# NUC400_v1 register map
File version: 1.0
Registers are 32-bit, read-write, reset 0x0 unless marked. A register's access mark holds for its fields unless they carry their own. Offsets are from the block's base; [hi:lo] are bit positions; 'fields as' and 'values as' point back to an identical list.

## EPWM0 — EPWM Register Map
Base 0x4005C000
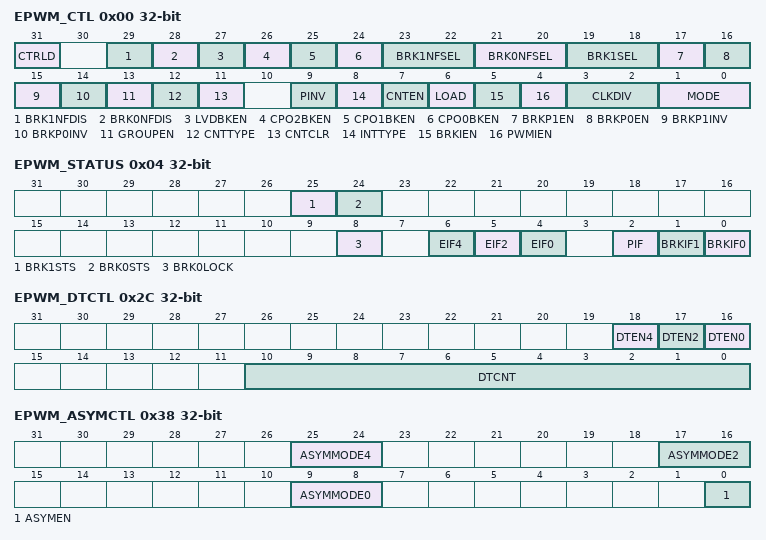
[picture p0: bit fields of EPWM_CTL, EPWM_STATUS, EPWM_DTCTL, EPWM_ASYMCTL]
0x00 EPWM_CTL — PWM Control Register
  [31] CTRLD — Center Reload Mode Enable Bit. This bit only work when EPWM operation at center aligned mode.
    0=EPWM reload compare register at the period point of PWM counter; 1=EPWM reload compare register at the center point of PWM counter
  [29] BRK1NFDIS — PWM Brake 1 Noise Filter Disable Bit
    0=Noise filter of PWM Brake 1 Enabled; 1=Noise filter of PWM Brake 1 Disabled
  [28] BRK0NFDIS — PWM Brake 0 Noise Filter Disable Bit
    0=Noise filter of PWM Brake 0 Enabled; 1=Noise filter of PWM Brake 0 Disabled
  [27] LVDBKEN — Low-Level Detection Trigger PWM Brake Function 1 Enable Bit
    0=Brake Function 1 triggered by Low-level detection Disabled; 1=Brake Function 1 triggered by Low-level detection Enabled
  [26] CPO2BKEN — CPO2 Digital Output As Brake 0 Source Enable Bit
    0=CPO2 as one brake source in Brake 0 Disabled; 1=CPO2 as one brake source in Brake 0 Enabled
  [25] CPO1BKEN — CPO1 Digital Output As Brake 0 Source Enable Bit
    0=CPO1 as one brake source in Brake 0 Disabled; 1=CPO1 as one brake source in Brake 0 Enabled
  [24] CPO0BKEN — CPO0 Digital Output As Brake0 Source Enable Bit
    0=CPO0 as one brake source in Brake 0 Disabled; 1=CPO0 as one brake source in Brake 0 Enabled
  [23:22] BRK1NFSEL — Brake 1 (BKPx1 Pin) Edge Detector Filter Clock Selection
    0=Filter clock = HCLK; 1=Filter clock = HCLK/2; 2=Filter clock = HCLK/4; 3=Filter clock = HCLK/16
  [21:20] BRK0NFSEL — Brake 0 (BKPx0 Pin) Edge Detector Filter Clock Selection
    values as BRK1NFSEL
  [19:18] BRK1SEL — Brake Function 1 Source Selection
    0=From external pin BKPx1 (x=0~1 for unit0~1); 1=From analog comparator 0 output (CPO0); 2=From analog comparator 1 output (CPO1); 3=From analog comparator 2 output (CPO2)
  [17] BRKP1EN — BKPx1 Pin Trigger Brake Function Enable Bit
    0=PWMx Brake Function 1 Disabled; 1=PWMx Brake Function 1 Enabled
  [16] BRKP0EN — BKPx0 Pin Trigger Brake Function0 Enable Bit
    0=PWMx Brake Function 0 Disabled; 1=PWMx Brake Function 0 Enabled
  [15] BRKP1INV — Inverse BKP1 State
    0=The state of pin BKPx1 is passed to the negative edge detector; 1=The inversed state of pin BKPx1 is passed to the negative edge detector
  [14] BRKP0INV — Inverse BKP0 State
    0=The state of pin BKPx0 is passed to the negative edge detector; 1=The inversed state of pin BKPx0 is passed to the negative edge detector
  [13] GROUPEN — Group Bit
    0=The signals timing of EPWM_CMPDAT0, EPWM_CMPDAT2 and EPWM_CMPDAT4 are independent; 1=Unify the signals timing of EPWM_CMPDAT0, EPWM_CMPDAT2 and EPWM_CMPDAT4 in the same phase which is controlled by EPWM_CMPDAT0
  [12] CNTTYPE — PWM Aligned Type Selection
    0=Edge-aligned type; 1=Centre-aligned type
  [11] CNTCLR — Clear PWM Counter Control. Note: It is automatically cleared by hardware.
    1=Clear 16-bit PWM counter to 000H
  [9] PINV — Inverse PWM Comparator Output. When PINV is set to high the PWM comparator output signals will be inversed, therefore the PWM Duty (in percentage) is changed to (1-Duty) before PINV is set to high.
    0=Not inverse PWM comparator output; 1=Inverse PWM comparator output
  [8] INTTYPE — PWM Interrupt Type Selection. Note: This bit is effective when PWM in central align mode only.
    0=PIF will be set if PWM counter underflow; 1=PIF will be set if PWM counter matches EPWM_PERIOD register
  [7] CNTEN — Start CNTEN Control
    0=The PWM stops running; 1=The PWM counter starts running
  [6] LOAD — Re-Load PWM Period Registers (EPWM_PERIOD) And PWM Compare Registers (EPWM_CMPDAT0~4) Control. Note: This bit is software write, hardware clear and always read zero.
    0=No action if written with 0. The value of PWM period register (EPWM_PERIOD) and PWM compare registers (EPWM_CMPDAT0~EPWM_CMPDAT4) are not loaded to PWM counter and Comparator registers; 1=Hardware will update the value of PWM period register (EPWM_PERIOD) and PWM compare registers (EPWM_CMPDAT0~EPWM_CMPDAT4) to PWM Counter and Comparator register at the time of PWM Counter matches PERIOD in edge and central aligned modes or at the time of PWM Counter down counts with underflow in central aligned mode
  [5] BRKIEN — Brake0 And Brak1 Interrupt Enable Bit
    0=Disabling flags BRKIF0 and BRKIF1 to trigger PWM interrupt; 1=Enabling flags BRKIF0 and BRKIF1 can trigger PWM interrupt
  [4] PWMIEN — PWM Interrupt Enable Bit
    0=Disabling flag PIF to trigger PWM interrupt; 1=Enabling flag PIF can trigger PWM interrupt
  [3:2] CLKDIV — PWM Clock Pre-Divider Selection
    0=PWM clock = EPWM_CLK; 1=PWM clock = EPWM_CLK/2; 2=PWM clock = EPWM_CLK/4; 3=PWM clock = EPWM_CLK/16
  [1:0] MODE — PWM Mode Selection
    0=Independent mode; 1=Pair/Complementary mode; 2=Synchronized mode
0x04 EPWM_STATUS — PWM Status Register
  [25] BRK1STS ro — Brake 1 Status (Read Only)
    0=PWM had been out of Brake 1 state; 1=PWM is in Brake 1 state
  [24] BRK0STS ro — Brake 0 Status (Read Only)
    0=PWM had been out of Brake 0 state; 1=PWM is in Brake 0 state
  [8] BRK0LOCK — PWM Brake0 Locked. Note: This bit must be cleared by writing 1 to it.
    0=Brake 0 state is released; 1=When PWM Brake detects a falling signal at BKP0, this flag will be set to high to indicate the Brake0 state is locked
  [6] EIF4 — PWMx_CH4 Edge Flag. Note: This bit must be cleared by writing 1 to it.
    0=The PWMx_CH4 doesn't toggle; 1=Hardware will set this flag to high at the time of PWMx_CH4 rising or falling. If EDGEIEN4(EPWM_EINTCTL[10]) = 0, this bit is set when PWMx_CH4 falling is detected. If EDGEIEN4(EPWM_EINTCTL[10]) = 1, this bit is set when PWMx_CH4 rising is detected.
  [5] EIF2 — PWMx_CH2 Edge Flag. Note: This bit must be cleared by writing 1 to it.
    0=The PWMx_CH2 doesn't toggle; 1=Hardware will set this flag to high at the time of PWMx_CH2 rising or falling. If EDGEIEN2(EPWM_EINTCTL[9]) = 0, this bit is set when PWMx_CH2 falling is detected. If EDGEIEN2(EPWM_EINTCTL[9])= 1, this bit is set when PWMx_CH2 rising is detected.
  [4] EIF0 — PWMx_CH0 Edge Flag. Note: This bit must be cleared by writing 1 to it.
    0=The PWMx_CH0 doesn't toggle; 1=Hardware will set this flag to high at the time of PWMx_CH0 rising or falling. If EDGEIEN0(EPWM_EINTCTL[8]) = 0, this bit is set when PWMx_CH0 falling is detected. If EDGEIEN0(EPWM_EINTCTL[8]) = 1, this bit is set when PWMx_CH0 rising is detected.
  [2] PIF — PWM Period Flag. Note: This bit must be cleared by writing 1 to it.
    0=PWM Counter has not up counted to the value of PERIOD or down counted with underflow; 1=Hardware will set this flag to high at the time of PWM Counter matches PERIOD in edge and Centre aligned modes or at the time of PWM Counter down counts with underflow in Centre aligned mode
  [1] BRKIF1 — PWM Brake1 Flag. Note: This bit must be cleared by writing 1 to it.
    0=PWM Brake 1 is able to poll falling signal at BKP1 and has not recognized any one; 1=When PWM Brake 1 detects a falling signal at pin BKP1, this flag will be set to high
  [0] BRKIF0 — PWM Brake0 Flag. Note: This bit must be cleared by writing 1 to it.
    0=PWM Brake 0 is able to poll falling signal at BKP0 and has not recognized any one; 1=When PWM Brake 0 detects a falling signal at BKP0, this flag will be set to high
0x08 EPWM_PERIOD — PWM Period Register
  [15:0] PERIOD — PWM Period Register. Edge aligned:
0x0C EPWM_CMPDAT0 — EPWM_CMPDAT0 Duty Register
  [15:0] CMP — PWM Duty Register. Edge aligned:
0x10 EPWM_CMPDAT2 — EPWM_CMPDAT2 Duty Register
  [15:0] CMP — PWM Duty Register. Edge aligned:
0x14 EPWM_CMPDAT4 — EPWM_CMPDAT4 Duty Register
  [15:0] CMP — PWM Duty Register. Edge aligned:
0x18 EPWM_MSKEN — PWM Mask Mode Enable Control Register
  [5:0] MSKEN — PWM Mask Enable Bits. The PWM generator signal will be masked when this bit is enabled. The corresponding EPWM_CHn channel will be output with EPWM_MSK[n] data.
    0=PWM generator signal is output to next stage; 1=PWM generator signal is masked and EPWM_MSK[n] is output to next stage
0x1C EPWM_MSK — PWM Mask Mode Data Register
  [5:0] MSKDAT — PWM Mask Data Bit
    0=Output logic low to EPWM_CHn; 1=Output logic high to EPWM_CHn
0x20 EPWM_ASYMCMP0 — Asymmetric EPWM_CMPDAT0 Duty Register
  [15:0] CMP — Asymmetric PWM Duty Register. When the asymmetric PWM function is enabled, this 16-bit field determines the second time compared value after PWM counter has matched with EPWM_CMPDATx in the first half PWM cycle.
0x24 EPWM_ASYMCMP2 — Asymmetric EPWM_CMPDAT2 Duty Register
  fields as EPWM_ASYMCMP0
0x28 EPWM_ASYMCMP4 — Asymmetric EPWM_CMPDAT4 Duty Register
  fields as EPWM_ASYMCMP0
0x2C EPWM_DTCTL — PWM Dead-time Control Register
  [18] DTEN4 — Dead-Time Insertion Enable Control for PWMx Pair (PWM_CH4, PWM_CH5). Dead-time insertion is only active when this pair of complementary PWM is enabled. If dead-time insertion is inactive, the outputs of pin pair are complementary without any delay.
    0=Dead-time insertion Disabled on the pin pair (PWM_CH4, PWM_CH5); 1=Dead-time insertion Enabled on the pin pair (PWM_CH4, PWM_CH5)
  [17] DTEN2 — Dead-Time Insertion Enable Control for PWMx Pair (PWM_CH2, PWM_CH3). Dead-time insertion is only active when this pair of complementary PWM is enabled. If dead-time insertion is inactive, the outputs of pin pair are complementary without any delay.
    0=Dead-time insertion Disabled on the pin pair (PWM_CH2, PWM_CH3); 1=Dead-time insertion Enabled on the pin pair (PWM_CH2, PWM_CH3)
  [16] DTEN0 — Dead-Time Insertion Enable Control for PWMx Pair (PWM_CH0, PWM_CH1). Dead-time insertion is only active when this pair of complementary PWM is enabled. If dead-time insertion is inactive, the outputs of pin pair are complementary without any delay.
    0=Dead-time insertion Disabled on the pin pair (PWM_CH0, PWM_CH1); 1=Dead-time insertion Enabled on the pin pair (PWM_CH0, PWM_CH1)
  [10:0] DTCNT — Dead-Time Counter. The dead-time can be calculated from the following formula:
0x30 EPWM_BRKOUT — PWM Brake Output
  [5:0] BRKOUT — PWM Brake Output. When PWM Brake is asserted, the PWM_CH0~5 output state before polarity control will follow bit0~5 setting, respectively.
    0=The PWM_CHn output before polarity control is low when Brake is asserted; 1=The PWM_CHn output before polarity control is high when Brake is asserted
0x34 EPWM_NPCTL — PWM Negative Polarity Control
  [5:0] NEGPOLAR — PWM Negative Polarity Control. The register bit controls polarity/active state of real PWM output.
    0=PWM_CHn output is active high; 1=PWM_CHn output is active low
0x38 EPWM_ASYMCTL — Asymmetric PWM Control Register
  [25:24] ASYMMODE4 — Asymmetric PWMx_CH4 Reload Mode Setting
    0=1. PWM compare register 4 is reload CMP (EPWM_CMPDAT4[15:0]) at PWM cycle start; 1=1. PWM compare register 4 is reload CMP (EPWM_CMPDAT4[15:0]) at PWM cycle start; 2=1. PWM compare register 4 is reload CMP (EPWM_CMPDAT4[15:0]) at PWM cycle start
  [17:16] ASYMMODE2 — Asymmetric PWMx_CH2 Reload Mode Setting
    0=1. PWM compare register 2 is reload CMP (EPWM_CMPDAT2[15:0]) at PWM cycle start; 1=1. PWM compare register 2 is reload CMP (EPWM_CMPDAT2[15:0]) at PWM cycle start; 2=1. PWM compare register 2 is reload PWM_Duty (PWMx2[15:0]) at PWM cycle start
  [9:8] ASYMMODE0 — Asymmetric PWMx_CH0 Reload Mode Setting
    0=1. PWM compare register 0 is reload CMP (EPWM_CMPDAT0[15:0]) at PWM cycle start; 1=1. PWM compare register 0 is reload CMP (EPWM_CMPDAT0[15:0]) at PWM cycle start; 2=1. PWM compare register 0 is reload CMP (EPWM_CMPDAT0[15:0]) at PWM cycle start
  [0] ASYMEN — Asymmetric PWM Enable Bit. Note: This control bit is only valid when PWM module is set in Centre-aligned mode.
    0=Asymmetric PWM function Disabled; 1=Asymmetric PWM function Enabled
0x3C EPWM_PERIODCNT — PIF Compared Counter
  [3:0] PERIODCNT — PIF Compared Counter. The register sets the count number which defines how many times of PWM period occurs to set bit PIF to request the PWM period interrupt. PIF will be set in every (1 + PERIODCNT[3:0]) times of PWM period or center point defined by INTTYPE when EPWM_CTL [8] occurred.
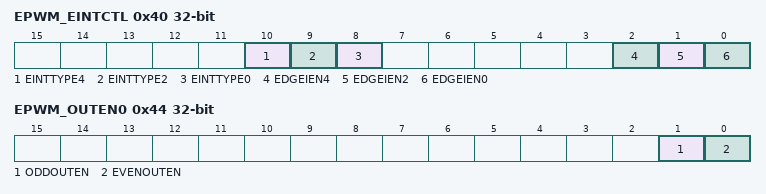
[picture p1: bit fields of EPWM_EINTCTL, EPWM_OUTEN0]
0x40 EPWM_EINTCTL — PWM Edge Interrupt Control Register
  [10] EINTTYPE4 — PWMx4 Edge Interrupt Type
    0=EIF4 will be set if falling edge is detected at PWMx4; 1=EIF4 will be set if rising edge is detected at PWMx4
  [9] EINTTYPE2 — PWMx2 Edge Interrupt Type
    0=EIF2 will be set if falling edge is detected at PWMx2; 1=EIF2 will be set if rising edge is detected at PWMx2
  [8] EINTTYPE0 — PWMx0 Edge Interrupt Type
    0=EIF0 will be set if falling edge is detected at PWMx0; 1=EIF0 will be set if rising edge is detected at PWMx0
  [2] EDGEIEN4 — PWMx4 Edge Interrupt Enable Bit
    0=Disable flag EIF4 to trigger PWM interrupt; 1=Enabling flag EIF4 can trigger PWM interrupt
  [1] EDGEIEN2 — PWMx2 Edge Interrupt Enable Bit
    0=Disabling flag EIF2 can trigger PWM interrupt; 1=Enabling flag EIF2 can trigger PWM interrupt
  [0] EDGEIEN0 — PWMx0 Edge Interrupt Enable Bit
    0=Disabling flag EIF0 to trigger PWM interrupt; 1=Enabling flag EIF0 can trigger PWM interrupt
0x44 EPWM_OUTEN0 — PWM Output Enable Control Register
  [1] ODDOUTEN — PWM Odd Ports Output Enable Bit
    0=PWM odd ports output Disabled (PWM even ports at tri-state); 1=PWM odd ports output Enabled
  [0] EVENOUTEN — PWM Even Ports Output Enable Bit
    0=PWM even ports output Disabled (PWM even ports at tri-state); 1=PWM even ports output Enabled

## EPWM1 — EPWM Register Map
Base 0x4005D000
Registers as EPWM0; these are added or differ:
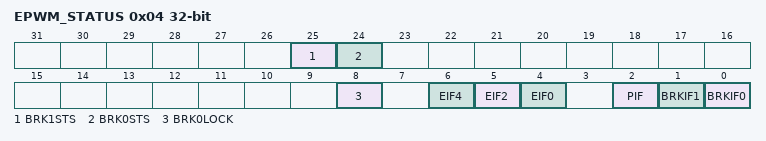
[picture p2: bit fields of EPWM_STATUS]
0x04 EPWM_STATUS — PWM Status Register
  [25] BRK1STS ro — Brake 1 Status (Read Only)
    0=PWM had been out of Brake 1 state; 1=PWM is in Brake 1 state
  [24] BRK0STS ro — Brake 0 Status (Read Only)
    0=PWM had been out of Brake 0 state; 1=PWM is in Brake 0 state
  [8] BRK0LOCK — PWM Brake0 Locked. Note: This bit must be cleared by writing 1 to it.
    0=Brake 0 state is released; 1=When PWM Brake detects a falling signal at BKP0, this flag will be set to high to indicate the Brake0 state is locked
  [6] EIF4 — PWMx_CH4 Edge Flag. Note: This bit must be cleared by writing 1 to it.
    0=The PWMx_CH4 doesn't toggle; 1=Hardware will set this flag to high at the time of PWMx_CH4 rising or falling. If EDGEIEN4(EPWM_EINTCTL[10]) = 0, this bit is set when PWMx_CH4 falling is detected. If EDGEIEN4(EPWM_EINTCTL[10]) = 1, this bit is set when PWMx_CH4 rising is detected
  [5] EIF2 — PWMx_CH2 Edge Flag. Note: This bit must be cleared by writing 1 to it.
    0=The PWMx_CH2 doesn't toggle; 1=Hardware will set this flag to high at the time of PWMx_CH2 rising or falling. If EDGEIEN2(EPWM_EINTCTL[9]) = 0, this bit is set when PWMx_CH2 falling is detected. If EDGEIEN2(EPWM_EINTCTL[9])= 1, this bit is set when PWMx_CH2 rising is detected
  [4] EIF0 — PWMx_CH0 Edge Flag. Note: This bit must be cleared by writing 1 to it.
    0=The PWMx_CH0 doesn't toggle; 1=Hardware will set this flag to high at the time of PWMx_CH0 rising or falling. If EDGEIEN0(EPWM_EINTCTL[8]) = 0, this bit is set when PWMx_CH0 falling is detected. If EDGEIEN0(EPWM_EINTCTL[8]) = 1, this bit is set when PWMx_CH0 rising is detected
  [2] PIF — PWM Period Flag. Note: This bit must be cleared by writing 1 to it.
    values as EPWM0.EPWM_STATUS.PIF
  [1] BRKIF1 — PWM Brake1 Flag. Note: This bit must be cleared by writing 1 to it.
    0=PWM Brake 1 is able to poll falling signal at BKP1 and has not recognized any one; 1=When PWM Brake 1 detects a falling signal at pin BKP1, this flag will be set to high
  [0] BRKIF0 — PWM Brake0 Flag. Note: This bit must be cleared by writing 1 to it.
    0=PWM Brake 0 is able to poll falling signal at BKP0 and has not recognized any one; 1=When PWM Brake 0 detects a falling signal at BKP0, this flag will be set to high
